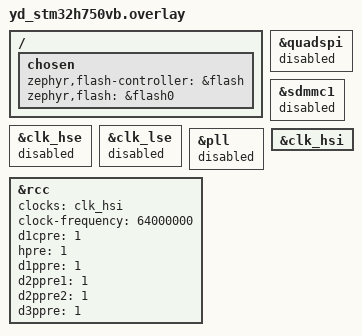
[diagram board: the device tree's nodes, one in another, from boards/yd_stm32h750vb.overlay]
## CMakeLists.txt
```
cmake_minimum_required(VERSION 3.13.1)
find_package(Zephyr REQUIRED HINTS $ENV{ZEPHYR_BASE})
project(daisy_seed_demo)

target_sources(app PRIVATE src/main.c)
```

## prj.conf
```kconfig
# Minimal config for Daisy Seed Renode demo
CONFIG_SYS_CLOCK_TICKS_PER_SEC=100

CONFIG_GPIO=y

CONFIG_SERIAL=y
CONFIG_UART_CONSOLE=y
CONFIG_CONSOLE=y
CONFIG_PRINTK=y
CONFIG_UART_STM32=y
CONFIG_UART_INTERRUPT_DRIVEN=y

CONFIG_PINCTRL=y
CONFIG_PINCTRL_STM32=y
```

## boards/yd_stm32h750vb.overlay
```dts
/*
 * Overlay for yd_stm32h750vb targeting Renode simulation.
 *
 * The board's default flash-controller is the external W25Q128 QSPI NOR.
 * Override it to the internal STM32H7 flash controller so the ELF is linked
 * to run from 0x08000000 (flashBank1 in Renode's stm32h743.repl).
 */

/ {
    chosen {
        zephyr,flash-controller = &flash;
        zephyr,flash = &flash0;
    };
};

/* QuadSPI (external NOR flash) is not needed for simulation */
&quadspi {
    status = "disabled";
};

/* SD card not needed */
&sdmmc1 {
    status = "disabled";
};

/*
 * Clock override for Renode simulation.
 *
 * The default board clock tree uses HSE (25 MHz external oscillator) + PLL to
 * reach 480 MHz. Renode's simplified RCC model never sets HSERDY / PLL1RDY
 * after the HAL enables them, so Zephyr's clock init hangs in a busy-wait loop
 * and main() is never reached.
 *
 * Use the internal HSI64 (64 MHz, no external oscillator) directly as sysclk.
 * HSI is always ready in Renode's RCC model so the clock init completes instantly.
 */
&clk_hse {
    status = "disabled";
};

&clk_lse {
    status = "disabled";
};

&pll {
    status = "disabled";
};

&clk_hsi {
    status = "okay";
};

&rcc {
    clocks = <&clk_hsi>;
    clock-frequency = <64000000>;
    d1cpre = <1>;
    hpre = <1>;
    d1ppre = <1>;
    d2ppre1 = <1>;
    d2ppre2 = <1>;
    d3ppre = <1>;
};
```

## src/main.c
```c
#include <zephyr/kernel.h>
#include <zephyr/sys/printk.h>
#include <zephyr/drivers/gpio.h>

/* led0 = PA15 (yellow LED, GPIO_ACTIVE_HIGH) */
#define LED_NODE DT_ALIAS(led0)
/* sw0  = PB3  (user button, GPIO_ACTIVE_LOW | GPIO_PULL_UP) */
#define BTN_NODE DT_ALIAS(sw0)

static const struct gpio_dt_spec led = GPIO_DT_SPEC_GET(LED_NODE, gpios);
static const struct gpio_dt_spec btn = GPIO_DT_SPEC_GET(BTN_NODE, gpios);

int main(void)
{
    printk("Daisy Seed demo started\n");

    if (!gpio_is_ready_dt(&led)) {
        printk("LED GPIO not ready\n");
        return -1;
    }
    if (!gpio_is_ready_dt(&btn)) {
        printk("Button GPIO not ready\n");
        return -1;
    }

    gpio_pin_configure_dt(&led, GPIO_OUTPUT_INACTIVE);
    gpio_pin_configure_dt(&btn, GPIO_INPUT);

    printk("Ready - press USER button to toggle PA15\n");

    bool prev_pressed = false;
    bool led_state    = false;

    while (1) {
        /* gpio_pin_get_dt returns logical level:
         * 1 = active (button pressed) due to GPIO_ACTIVE_LOW
         * 0 = inactive (button released)
         */
        bool pressed = gpio_pin_get_dt(&btn) != 0;

        if (pressed && !prev_pressed) {
            led_state = !led_state;
            gpio_pin_set_dt(&led, led_state ? 1 : 0);
            printk("BUTTON PRESSED - OUTPUT %s\n", led_state ? "HIGH" : "LOW");
        }

        prev_pressed = pressed;
        k_msleep(50);
    }

    return 0;
}
```
